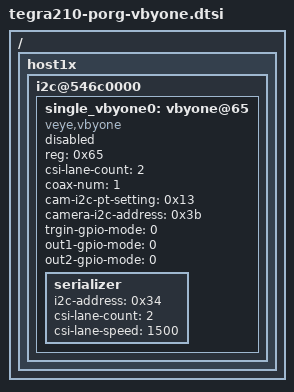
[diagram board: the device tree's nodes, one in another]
/*
 * Copyright (c) 2018-2019, NVIDIA CORPORATION.  All rights reserved.
 *
 * This program is free software; you can redistribute it and/or modify
 * it under the terms of the GNU General Public License as published by
 * the Free Software Foundation; either version 2 of the License, or
 * (at your option) any later version.
 *
 * This program is distributed in the hope that it will be useful, but WITHOUT
 * ANY WARRANTY; without even the implied warranty of MERCHANTABILITY or
 * FITNESS FOR A PARTICULAR PURPOSE.  See the GNU General Public License for
 * more details.
 *
 * You should have received a copy of the GNU General Public License
 * along with this program.  If not, see <http://www.gnu.org/licenses/>.
 */

/ {
    host1x{
	i2c@546c0000 {
            single_vbyone0: vbyone@65 {
            compatible = "veye,vbyone";

            reg = <0x65>;
            status = "disabled";
            csi-lane-count = <2>;
            coax-num = <1>;
            cam-i2c-pt-setting = <0x13>;
            camera-i2c-address=<0x3b>;
            
            trgin-gpio-mode = <0>;
            out1-gpio-mode = <0>;
            out2-gpio-mode = <0>;
            
            serializer {
                i2c-address=<0x34>;
                csi-lane-count = <2>;
                csi-lane-speed = <1500>;
                };
            };
        };
    };
};
